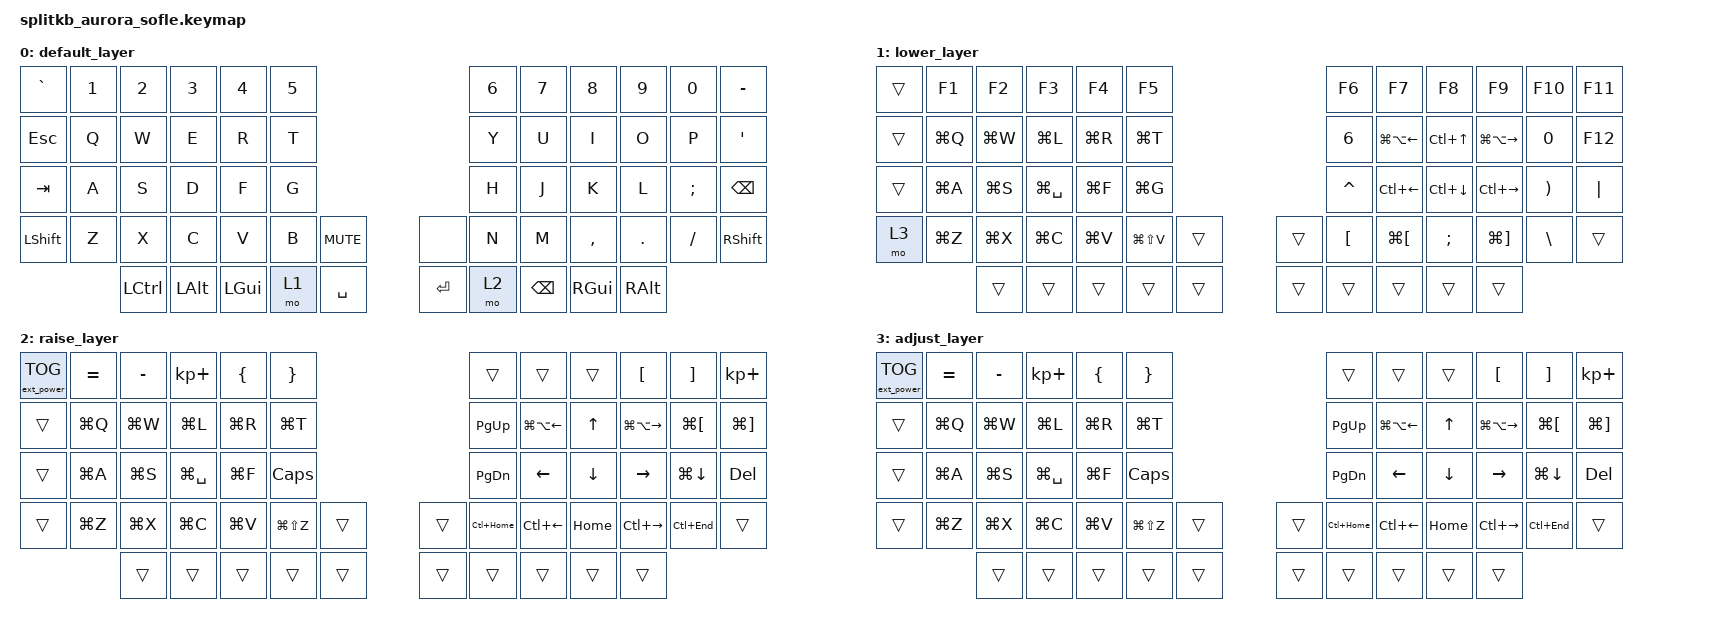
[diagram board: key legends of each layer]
/*
* Copyright (c) 2020 The ZMK Contributors
*
* SPDX-License-Identifier: MIT
*/

#include <behaviors.dtsi>
#include <dt-bindings/zmk/keys.h>
#include <dt-bindings/zmk/bt.h> 
#include <dt-bindings/zmk/ext_power.h>


#define DEFAULT 0
#define LOWER 1
#define RAISE 2
#define ADJUST 3  



/ {
	
	
	conditional_layers {
		compatible = "zmk,conditional-layers";
		tri_layer {
			if-layers = <1 2>;
			then-layer = <3>;
		};
	};
	
	keymap {
		
		
		compatible = "zmk,keymap";
		
		default_layer {
			// ------------------------------------------------------------------------------------------------------------
			// |  `    |  1  |  2  |  3   |  4   |  5   |                         |  6   |  7    |  8    |  9   |   0   |   -   |
			// |  ESC  |  Q  |  W  |  E   |  R   |  T   |                         |  Y   |  U    |  I    |  O   |   P   |   '   |
			// |  TAB  |  A  |  S  |  D   |  F   |  G   |                         |  H   |  J    |  K    |  L   |   ;   | BKSPC |
			// | SHIFT |  Z  |  X  |  C   |  V   |  B   |  MUTE  |        |       |  N   |  M    |  ,    |  .   |   /   | SHIFT |
			//               | CTRL | ALT  | GUI | LOWER|  SPACE |        | ENTER | RAISE| RAISE(tog)   | GUI   |  ALT |
			bindings = <
			&kp GRAVE &kp N1 &kp N2   &kp N3   &kp N4    &kp N5                       &kp N6 &kp N7    &kp N8    &kp N9   &kp N0   &kp MINUS
			&kp ESC   &kp Q  &kp W    &kp E    &kp R     &kp T                        &kp Y  &kp U     &kp I     &kp O    &kp P    &kp SQT
			&kp TAB   &kp A  &kp S    &kp D    &kp F     &kp G                        &kp H  &kp J     &kp K     &kp L    &kp SEMI &kp BSPC
			&kp LSHFT &kp Z  &kp X    &kp C    &kp V     &kp B  &kp C_MUTE &none      &kp N  &kp M     &kp COMMA &kp DOT  &kp FSLH &kp RSHFT
			&kp LCTRL &kp LALT &kp LGUI &mo 1  &kp SPACE    &kp RET  &mo 2  &kp BSPC  &kp RGUI  &kp RALT
			>;
			
			sensor-bindings = <&inc_dec_kp C_VOL_UP C_VOL_DN &inc_dec_kp PG_UP PG_DN>;
		};
		
		lower_layer {
			// ------------------------------------------------------------------------------------------------------------
			// |       |  F1 |  F2 |  F3  |  F4  |  F5  |                   |  F6  |  F7   |  F8   |  F9  |  F10  |  F11  |
			// |       | QUIT|CLOSE| URL  |RFRSH |N_TAB |                   |   6  |   L_TAB  |   U_SP   |   R_TAB  |    0  |  F12  |
			// |       | ALL | SAVE| SPOT | FIND | CMD_G|                   |  ^   |  L_SP    |  D_SP    |  r_SP    |   )   |   |   |
			// |       |UNDO | CUT | COPY | PASTE| REDO |        |  |       |  [   |  BACK    |  ;       |  FWD     |   \   |       |
			//               |     |      |      |      |        |  |       |      |       |       |      |
			bindings = <
			&trans      &kp F1    &kp F2    &kp F3        &kp F4    &kp F5                        &kp F6    &kp F7            &kp F8       &kp F9               &kp F10   &kp F11
			&trans      &kp LG(Q) &kp LG(W) &kp LG(L)     &kp LG(R) &kp LG(T)                     &kp N6    &kp LG(LA(LEFT))  &kp LC(UP)   &kp LG(LA(RIGHT))    &kp N0    &kp F12
			&trans      &kp LG(A) &kp LG(S) &kp LG(SPACE) &kp LG(F) &kp LG(G)                     &kp CARET &kp LC(LEFT)      &kp LC(DOWN) &kp LC(RIGHT)        &kp RPAR  &kp PIPE
			&mo 3       &kp LG(Z) &kp LG(X) &kp LG(C)     &kp LG(V) &kp LG(LS(V)) &trans   &trans &kp LBKT  &kp LG(LBKT)      &kp SEMI     &kp LG(RBKT)         &kp BSLH  &trans
			&trans    &trans        &trans    &trans        &trans   &trans &trans    &trans            &trans       &trans
			>;
			
			sensor-bindings = <&inc_dec_kp C_VOL_UP C_VOL_DN &inc_dec_kp PG_UP PG_DN>;
		};
		
		raise_layer {
			// ------------------------------------------------------------------------------------------------------------
			// |OLED |  =   |  -   |  +    |   {   |   }  |                |      |       |       |  [   |   ]    |   +   |
			// |     | QUIT | CLOSE| URL   | RFRSH | N_TAB|                | PG_UP | L_TAB|   ^   | R_TAB|  BACK  |  FWD  |
			// |     | ALL  | SAVE | SPOT  | FIND  | CAPS |                | PG_DN |   <- |   v   |  ->  | CMD_DWN|  DEL  |
			// |     | UNDO | CUT  | COPY  | PASTE | REDO |      |  |      | HOME  | HOME |       | END  |  END   |       |
			//              |      |       |       |      |      |  |      |       |      |       |      |
			bindings = <
			&ext_power EP_TOG &kp EQUAL    &kp MINUS    &kp KP_PLUS  &kp LBRC     &kp RBRC                        &trans       &trans       &trans         &kp LBKT         &kp RBKT     &kp KP_PLUS
			&trans            &kp LG(Q)    &kp LG(W)    &kp LG(L)    &kp LG(R)    &kp LG(T)                       &kp PG_UP    &kp LG(LA(LEFT)) &kp UP     &kp LG(LA(RIGHT))&kp LG(LBKT) &kp LG(RBKT) 
			&trans            &kp LG(A)    &kp LG(S)    &kp LG(SPACE) &kp LG(F)   &kp CLCK                        &kp PG_DN    &kp LEFT     &kp DOWN       &kp RIGHT        &kp LG(DOWN) &kp DEL
			&trans            &kp LG(Z)    &kp LG(X)    &kp LG(C)    &kp LG(V)    &kp LG(LS(Z)) &trans   &trans   &kp LC(HOME) &kp LC(LEFT) &kp HOME       &kp LC(RIGHT)    &kp LC(END)  &trans
			&trans       &trans       &trans       &trans        &trans   &trans   &trans    &trans       &trans            &trans
			>;
			
			sensor-bindings = <&inc_dec_kp C_VOL_UP C_VOL_DN &inc_dec_kp PG_UP PG_DN>;
		};
		
		
		
		
		
		
		adjust_layer {
			// ------------------------------------------------------------------------------------------------------------
			// |OLED |  =   |  -   |  +    |   {   |   }  |                |      |       |       |  [   |   ]    |   +   |
			// |     | QUIT | CLOSE| URL   | RFRSH | N_TAB|                | PG_UP | L_TAB|   ^   | R_TAB|  BACK  |  FWD  |
			// |     | ALL  | SAVE | SPOT  | FIND  | CAPS |                | PG_DN |   <- |   v   |  ->  | CMD_DWN|  DEL  |
			// |     | UNDO | CUT  | COPY  | PASTE | REDO |      |  |      | HOME  | HOME |       | END  |  END   |       |
			//              |      |       |       |      |      |  |      |       |      |       |      |
			bindings = <
			&ext_power EP_TOG &kp EQUAL    &kp MINUS    &kp KP_PLUS  &kp LBRC     &kp RBRC                        &trans       &trans       &trans         &kp LBKT         &kp RBKT     &kp KP_PLUS
			&trans            &kp LG(Q)    &kp LG(W)    &kp LG(L)    &kp LG(R)    &kp LG(T)                       &kp PG_UP    &kp LG(LA(LEFT)) &kp UP     &kp LG(LA(RIGHT))&kp LG(LBKT) &kp LG(RBKT) 
			&trans            &kp LG(A)    &kp LG(S)    &kp LG(SPACE) &kp LG(F)   &kp CLCK                        &kp PG_DN    &kp LEFT     &kp DOWN       &kp RIGHT        &kp LG(DOWN) &kp DEL
			&trans            &kp LG(Z)    &kp LG(X)    &kp LG(C)    &kp LG(V)    &kp LG(LS(Z)) &trans   &trans   &kp LC(HOME) &kp LC(LEFT) &kp HOME       &kp LC(RIGHT)    &kp LC(END)  &trans
			&trans       &trans       &trans       &trans        &trans   &trans   &trans    &trans       &trans            &trans
			>;
			
			sensor-bindings = <&inc_dec_kp C_VOL_UP C_VOL_DN &inc_dec_kp PG_UP PG_DN>;
		};
		
		
	};
	
	
};


/*
ideas:

dbl tap home/end = ctrl + home/end
//	paste and match style (shift + paste)

hold esc / both modifiers for force quit
both modifiers + arrows = music controls
opening and selecting music from folder?
both modifiers + numbers? = open/focus Finder TextEdit Vlc




raise = navigation arrows
raise + lower = space navigation arrows
!!!!!!then will be able to toggle raise layer while momentary lower to switch spaces/tabs
????also add excel functions to left hand (paste text values, right click menu, macros)



excel:
column filter menu???
cmd+; for date

shift+f10(lower+0) = right click menu
F2 = edit text in excel cell. (lower+E for edit?)
cmd+pgup/pgdwn = navigate tabs


paste text???  (ALT, E, S, V) or (ALT H V)
filter column (select top row of column??, ALT+DWN, F, A)
macros for cell color selectiom (ALT, H, H, LEFT, DOWN, ENTER), (ALT, H, H, LEFT, DOWN, DOWN, DOWN, ENTER)
create new tab, paste and enter OR copy/paste into address bar (CMD+L, CMD+V, ENTER)

*/
